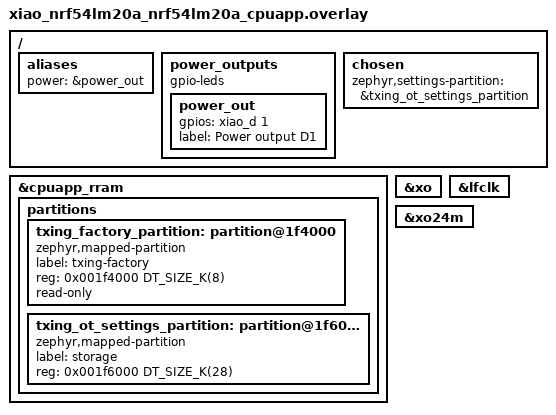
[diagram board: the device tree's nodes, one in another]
/* Shared XIAO nRF54LM20A D1 output and TXN1/OpenThread storage layout. */
/ {
	aliases {
		power = &power_out;
	};

	power_outputs {
		compatible = "gpio-leds";

		power_out: power_out {
			gpios = <&xiao_d 1 GPIO_ACTIVE_HIGH>;
			label = "Power output D1";
		};
	};

	chosen {
		zephyr,settings-partition = &txing_ot_settings_partition;
	};
};

&cpuapp_rram {
	partitions {
		/delete-node/ partition@1f4000;

		txing_factory_partition: partition@1f4000 {
			compatible = "zephyr,mapped-partition";
			label = "txing-factory";
			reg = <0x001f4000 DT_SIZE_K(8)>;
			read-only;
		};

		txing_ot_settings_partition: partition@1f6000 {
			compatible = "zephyr,mapped-partition";
			label = "storage";
			reg = <0x001f6000 DT_SIZE_K(28)>;
		};
	};
};

/*
 * Zephyr's split Nordic clock drivers require the child clock nodes to be
 * enabled separately.  The LM20A temperature sensor used by the 802.15.4
 * radio calibration path requires xo; keep the complete stock LM20A clock set
 * aligned with the Nordic development-board configuration.
 */
&xo {
	status = "okay";
};

&lfclk {
	status = "okay";
};

&xo24m {
	status = "okay";
};
